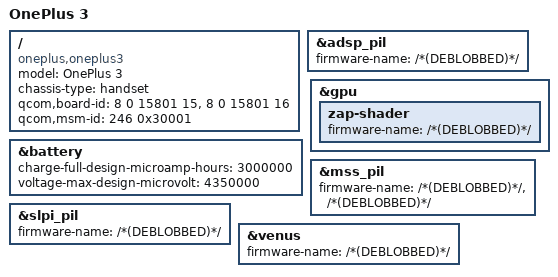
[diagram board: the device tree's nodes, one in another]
// SPDX-License-Identifier: GPL-2.0-only
/*
 * Copyright (c) 2022, Harry Austen <hpausten@protonmail.com>
 */

/dts-v1/;

#include "msm8996-oneplus-common.dtsi"

/ {
	model = "OnePlus 3";
	compatible = "oneplus,oneplus3", "qcom,msm8996";
	chassis-type = "handset";
	qcom,board-id = <8 0 15801 15>, <8 0 15801 16>;
	qcom,msm-id = <246 0x30001>;
};

&adsp_pil {
	firmware-name = "/*(DEBLOBBED)*/";
	status = "okay";
};

&battery {
	charge-full-design-microamp-hours = <3000000>;
	voltage-max-design-microvolt = <4350000>;
};

&gpu {
	status = "okay";

	zap-shader {
		firmware-name = "/*(DEBLOBBED)*/";
	};
};

&mss_pil {
	firmware-name = "/*(DEBLOBBED)*/",
			"/*(DEBLOBBED)*/";
	status = "okay";
};

&slpi_pil {
	firmware-name = "/*(DEBLOBBED)*/";
	status = "okay";
};

&venus {
	firmware-name = "/*(DEBLOBBED)*/";
	status = "okay";
};
